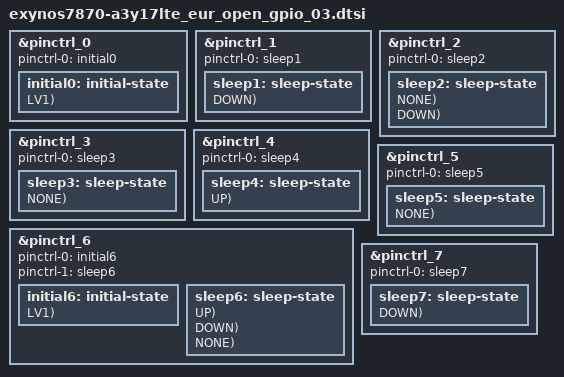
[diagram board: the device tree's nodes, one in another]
/*
 * Copyright (c) 2016 Samsung Electronics Co., Ltd.
 *		http://www.samsung.com
 *
 * This program is free software; you can redistribute it and/or modify
 * it under the terms of the GNU General Public License version 2 as
 * published by the Free Software Foundation.
*/

#include "exynos_gpio_config_macros.dtsi"

/* 0x139F_0000(ALIVE): gpa0~2, gpq0 */
&pinctrl_0 {
	pinctrl-names = "default";
	pinctrl-0 = <&initial0>;
	initial0: initial-state {
		PIN_IN(gpa0-7, NONE, LV1);	/* MCU_AP_INT */
		PIN_IN(gpq0-1, DOWN, LV1);	/* NC */
	};
	/*
	 * Note:
	 *   Please do not make "sleep-state" node for GPA group GPIOs.
	 *   GPA group doesn't have power-down status.
	 */
};

/* 0x148C_0000(DISPAUD): gpz0~2 */
&pinctrl_1 {
	pinctrl-names = "sleep";
	pinctrl-0 = <&sleep1>;
	sleep1: sleep-state {
		PIN_SLP(gpz0-0, INPUT, DOWN);	/* BT_PCM_LRCK */
		PIN_SLP(gpz0-1, INPUT, DOWN);	/* BT_PCM_CLK */
		PIN_SLP(gpz0-2, INPUT, DOWN);	/* BT_PCM_D_IN */
		PIN_SLP(gpz0-3, INPUT, DOWN);	/* BT_PCM_D_OUT */

		PIN_SLP(gpz1-0, INPUT, DOWN);	/* AMP/BB_I2S_LRCK */
		PIN_SLP(gpz1-1, INPUT, DOWN);	/* AMP_I2S_BCLK */
		PIN_SLP(gpz1-2, INPUT, DOWN);	/* BB_I2S_DI */
		PIN_SLP(gpz1-3, INPUT, DOWN);	/* AMP/BB_I2S_DO */
		PIN_SLP(gpz1-5, INPUT, DOWN);	/* AMP_I2S_D_IN */
		
		PIN_SLP(gpz2-0, INPUT, DOWN);	/* FM_I2S_SYNC */
		PIN_SLP(gpz2-1, INPUT, DOWN);	/* FM_I2S_CLK */
		PIN_SLP(gpz2-2, INPUT, DOWN);	/* FM_I2S_DI */
		PIN_SLP(gpz2-3, INPUT, DOWN);	/* NC */
	};
};

/* 0x139E_0000(ESE): gpc7 */
&pinctrl_2 {
	pinctrl-names = "sleep";
	pinctrl-0 = <&sleep2>;
	sleep2: sleep-state {
		PIN_SLP(gpc7-0, OUT0, NONE);	/* BTP_SPI_CLK */
		PIN_SLP(gpc7-1, OUT0, NONE);	/* BTP_SPI_CS_N */
		PIN_SLP(gpc7-2, INPUT, DOWN);	/* BTP_SPI_MISO */
		PIN_SLP(gpc7-3, OUT0, NONE);	/* BTP_SPI_MOSI */
		PIN_SLP(gpc7-4, PREV, NONE);	/* BTP_CHECK */
	};
};

/* 0x1375_0000(FSYS): gpr0~4 */
&pinctrl_3 {
	pinctrl-names = "sleep";
	pinctrl-0 = <&sleep3>;
	sleep3: sleep-state {
		PIN_SLP(gpr0-1, OUT1, NONE);	/* EMMC_CMD */
	};
};

/* 0x1053_0000(MIF): gpm0 */
&pinctrl_4 {
	pinctrl-names = "sleep";
	pinctrl-0 = <&sleep4>;
	sleep4: sleep-state {
		PIN_SLP(gpm0-0, PREV, UP);	/* PMIC_SDA_1P8 */
		PIN_SLP(gpm0-1, PREV, UP);	/* PMIC_SCL_1P8 */
	};
};

/* 0x139C_0000(NFC): gpc2 */
&pinctrl_5 {
	pinctrl-names = "sleep";
	pinctrl-0 = <&sleep5>;
	sleep5: sleep-state {
		PIN_SLP(gpc2-0, INPUT, NONE);	/* TSP_SDA_1P8 */
		PIN_SLP(gpc2-1, INPUT, NONE);	/* TSP_SCL_1P8 */
		PIN_SLP(gpc2-2, PREV, NONE);	/* NFC_EN */
		PIN_SLP(gpc2-3, PREV, NONE);	/* NFC_CLK_REQ */
	};
};

/* 0x139B_0000(TOP): gpb0, gpc0~1, gpc4~6, gpc8~9, gpd1~4, gpe0, gpf0~4 */
&pinctrl_6 {
	pinctrl-names = "default","sleep";
	pinctrl-0 = <&initial6>;
	pinctrl-1 = <&sleep6>;
	initial6: initial-state {
		PIN_IN(gpc0-1, DOWN, LV1);	/* NC */
		PIN_IN(gpc0-2, DOWN, LV1);	/* NC */
		
		PIN_OUT_SET(gpd1-1, 0, LV1);	/* CAM_AF_2P8_EN */
		PIN_IN(gpd1-3, DOWN, LV1);	/* NC */
		PIN_IN(gpd1-5, DOWN, LV1);	/* NC */

		PIN_OUT_SET(gpd2-3, 1, LV1);	/* MCU_RST_N */
		PIN_IN(gpd2-4, NONE, LV1);	/* HW_REV0 */
		PIN_IN(gpd2-5, NONE, LV1);	/* HW_REV1 */

		PIN_IN(gpd3-0, NONE, LV1);	/* HW_REV2 */
		PIN_IN(gpd3-1, NONE, LV1);	/* DS_DET */
		PIN_IN(gpd3-7, NONE, LV1);	/* MCU_AP_INT2 */

		PIN_OUT_SET(gpd4-2, 1, LV1);	/* AP_MCU_INT */
		PIN_OUT_SET(gpd4-3, 1, LV1);	/* SHUB_BOOT0 */

		PIN_IN(gpf4-4, DOWN, LV1);	/* NC */
	};
	sleep6: sleep-state {
		PIN_SLP(gpb0-0, INPUT, UP);	/* BT_UART_RXD */
		PIN_SLP(gpb0-1, OUT1, UP);	/* BT_UART_TXD */
		PIN_SLP(gpb0-2, INPUT, UP);	/* BT_UART_CTS */
		PIN_SLP(gpb0-3, OUT1, UP);	/* BT_UART_RTS */

		PIN_SLP(gpc0-1, INPUT, DOWN);	/* NC */
		PIN_SLP(gpc0-2, INPUT, DOWN);	/* NC */

		/* IF_PMIC_SDA_1P8 : exynos7870-pinctrl.dtsi */
		/* IF_PMIC_SCL_1P8 : exynos7870-pinctrl.dtsi */
		PIN_SLP(gpc1-2, INPUT, NONE);	/* FM_SDA_1P8 */
		PIN_SLP(gpc1-3, INPUT, NONE);	/* FM_SCL_1P8 */

		PIN_SLP(gpc4-0, INPUT, NONE);	/* FG_SDA_1P8 */
		PIN_SLP(gpc4-1, INPUT, NONE);	/* FG_SCL_1P8 */
		PIN_SLP(gpc4-2, OUT1, UP);	/* SHUB_SPI_CLK */
		PIN_SLP(gpc4-3, OUT1, UP);	/* SHUB_SPI_CS_N */

		PIN_SLP(gpc5-0, INPUT, DOWN);	/* SHUB_SPI_MISO */
		PIN_SLP(gpc5-1, OUT1, UP);	/* SHUB_SPI_MOSI */

		PIN_SLP(gpc6-0, INPUT, DOWN);	/* ESE_SPI_CLK */
		PIN_SLP(gpc6-1, INPUT, DOWN);	/* NC */
		PIN_SLP(gpc6-2, INPUT, DOWN);	/* ESE_SPI_MISO */
		PIN_SLP(gpc6-3, INPUT, DOWN);	/* ESE_SPI_MOSI */

		PIN_SLP(gpc8-0, INPUT, NONE);	/* TOUCH_SDA_1P8 */
		PIN_SLP(gpc8-1, INPUT, NONE);	/* TOUCH_SCL_1P8 */

		PIN_SLP(gpc9-0, INPUT, NONE);	/* AMP_SDA_1P8 */
		PIN_SLP(gpc9-1, INPUT, NONE);	/* AMP_SCL_1P8 */

		PIN_SLP(gpd1-0, PREV, NONE);	/* WRSTB_IN */
		PIN_SLP(gpd1-1, OUT0, DOWN);	/* CAM_AF_2P8_EN */
		PIN_SLP(gpd1-2, PREV, NONE);	/* FM_RST */
		PIN_SLP(gpd1-3, INPUT, DOWN);	/* NC */
		PIN_SLP(gpd1-4, INPUT, DOWN);	/* FG_ERR */
		PIN_SLP(gpd1-5, INPUT, DOWN);	/* NC */
		PIN_SLP(gpd1-6, OUT1, UP);	/* VDD_TOUCH_2P8_EN */

		PIN_SLP(gpd2-0, INPUT, DOWN);	/* NC */
		PIN_SLP(gpd2-1, PREV, NONE);	/* VDD_NFC_EN */
		PIN_SLP(gpd2-2, PREV, NONE);	/* MST_PWR_EN */
		PIN_SLP(gpd2-3, PREV, NONE);	/* MCU_RST_N */
		PIN_SLP(gpd2-4, INPUT, NONE);	/* HW_REV0 */
		PIN_SLP(gpd2-5, INPUT, NONE);	/* HW_REV1 */

		PIN_SLP(gpd3-0, INPUT, NONE);	/* HW_REV2 */
		PIN_SLP(gpd3-1, INPUT, NONE);	/* DS_DET */
		PIN_SLP(gpd3-2, PREV, NONE);	/* CAM_FLASH_EN */
		PIN_SLP(gpd3-3, PREV, NONE);	/* CAM_FLASH_SET */
		PIN_SLP(gpd3-4, PREV, NONE);	/* MLCD_RST */
		PIN_SLP(gpd3-5, INPUT, DOWN);	/* PCD_INT */
		PIN_SLP(gpd3-6, PREV, NONE);	/* WLAN_EN */
		PIN_SLP(gpd3-7, PREV, NONE);	/* MCU_AP_INT2 */

		PIN_SLP(gpd4-0, PREV, NONE);	/* BT_EN */
		PIN_SLP(gpd4-1, PREV, DOWN);	/* NFC_FIRM */
		PIN_SLP(gpd4-2, PREV, NONE);	/* AP_MCU_INT */
		PIN_SLP(gpd4-3, PREV, NONE);	/* SHUB_BOOT0 */
		PIN_SLP(gpd4-4, INPUT, DOWN);	/* NC */
		PIN_SLP(gpd4-5, PREV, DOWN);	/* BTP_LDO_EN */
		PIN_SLP(gpd4-6, PREV, DOWN);	/* BTP_RST_N */

		PIN_SLP(gpe0-0, INPUT, DOWN);	/* CAM_MCLK */
		PIN_SLP(gpe0-1, INPUT, DOWN);	/* VTCAM_MCLK */
		PIN_SLP(gpe0-2, INPUT, DOWN);	/* DISP_TE */

		PIN_SLP(gpf0-0, INPUT, DOWN);	/* MAIN_CAM_SDA_1P8 */
		PIN_SLP(gpf0-1, INPUT, DOWN);	/* MAIN_CAM_SCL_1P8 */
		PIN_SLP(gpf0-2, INPUT, DOWN);	/* VTCAM_SDA_1P8 */
		PIN_SLP(gpf0-3, INPUT, DOWN);	/* VTCAM_SCL_1P8 */

		PIN_SLP(gpf1-0, INPUT, DOWN);	/* CAM_AF_EEP_SDA_1P8 */
		PIN_SLP(gpf1-1, INPUT, DOWN);	/* CAM_AF_EEP_SCL_1P8 */

		PIN_SLP(gpf2-0, INPUT, NONE);	/* NFC_SDA_1P8 */
		PIN_SLP(gpf2-1, INPUT, NONE);	/* NFC_SCL_1P8 */

		PIN_SLP(gpf3-0, PREV, NONE);	/* WLAN_DCDC_EN */
		PIN_SLP(gpf3-1, INPUT, DOWN);	/* VTCAM_RST_N */
		PIN_SLP(gpf3-2, OUT0, DOWN);	/* VDD_CAM_IO_1P8_EN */
		PIN_SLP(gpf3-3, INPUT, DOWN);	/* CAM_RST */

		PIN_SLP(gpf4-0, OUT0, DOWN);	/* VDD_NFC_ESE_EN */
		PIN_SLP(gpf4-1, OUT0, DOWN);	/* CAM_SENSOR_CORE_EN */
		PIN_SLP(gpf4-2, INPUT, DOWN);	/* NC */
		PIN_SLP(gpf4-3, INPUT, DOWN);	/* DISP_TE */
		PIN_SLP(gpf4-4, INPUT, DOWN);	/* NC */
	};
};

/* 0x139D_0000(MST&ESE): gpc3 */
&pinctrl_7 {
	pinctrl-names = "sleep";
	pinctrl-0= <&sleep7>;
	sleep7: sleep-state {
		PIN_SLP(gpc3-0, PREV, DOWN);	/* MST_DATA_B(EN) */
		PIN_SLP(gpc3-1, PREV, DOWN);	/* MST_DATA_A */
		PIN_SLP(gpc3-2, INPUT, DOWN);	/* ESE_SPI_CS_N */
	};
};
